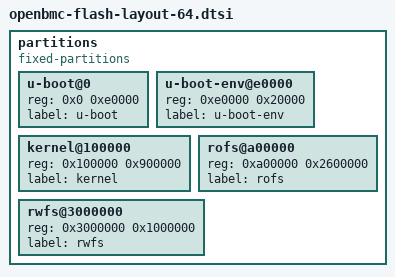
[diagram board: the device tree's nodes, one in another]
// SPDX-License-Identifier: GPL-2.0+

partitions {
	compatible = "fixed-partitions";
	#address-cells = <1>;
	#size-cells = <1>;

	u-boot@0 {
		reg = <0x0 0xe0000>; // 896KB
		label = "u-boot";
	};

	u-boot-env@e0000 {
		reg = <0xe0000 0x20000>; // 128KB
		label = "u-boot-env";
	};

	kernel@100000 {
		reg = <0x100000 0x900000>; // 9MB
		label = "kernel";
	};

	rofs@a00000 {
		reg = <0xa00000 0x2600000>; // 38MB
		label = "rofs";
	};

	rwfs@3000000 {
		reg = <0x3000000 0x1000000>; // 16MB
		label = "rwfs";
	};
};
